# STM32G0B1 register map
File version: 1.5
CPU: CM0 r0p1, little endian, MPU, no FPU, 4 interrupt priority bits
Registers are 32-bit, read-write, reset 0x0 unless marked. A register's access mark holds for its fields unless they carry their own. Offsets are from the block's base; [hi:lo] are bit positions; {n}, {i} and the like mark numbered series.

## RCC — Reset and clock control
Base 0x40021000
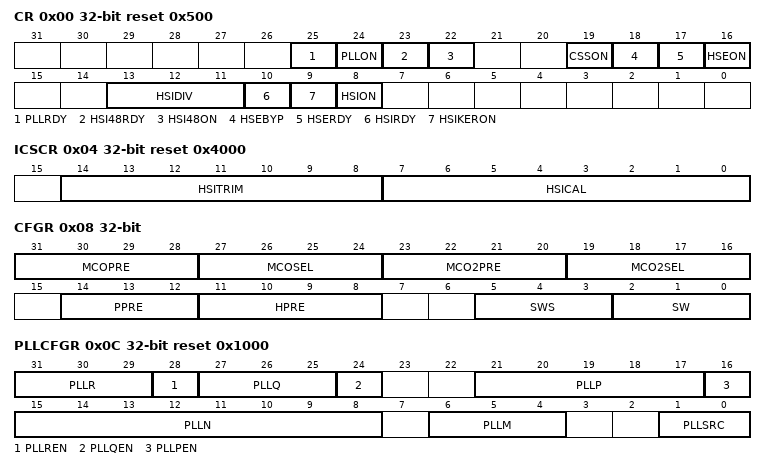
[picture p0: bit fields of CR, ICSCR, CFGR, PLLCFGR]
0x00 CR reset 0x500 — Clock control register
  [25] PLLRDY ro — PLL clock ready flag
  [24] PLLON — PLL enable
  [23] HSI48RDY ro
  [22] HSI48ON
  [19] CSSON — Clock security system enable
  [18] HSEBYP — HSE crystal oscillator bypass
  [17] HSERDY — HSE clock ready flag
  [16] HSEON — HSE clock enable
  [13:11] HSIDIV — HSI16 clock division factor
  [10] HSIRDY ro — HSI16 clock ready flag
  [9] HSIKERON — HSI16 always enable for peripheral kernels
  [8] HSION — HSI16 clock enable
0x04 ICSCR access per field reset 0x4000 — Internal clock sources calibration register
  [14:8] HSITRIM rw — HSI16 clock trimming
  [7:0] HSICAL ro — HSI16 clock calibration
0x08 CFGR access per field — Clock configuration register
  [31:28] MCOPRE rw — Microcontroller clock output prescaler
  [27:24] MCOSEL rw — Microcontroller clock output
  [23:20] MCO2PRE rw
  [19:16] MCO2SEL rw
  [14:12] PPRE rw — APB prescaler
  [11:8] HPRE rw — AHB prescaler
  [5:3] SWS ro — System clock switch status
  [2:0] SW rw — System clock switch
0x0C PLLCFGR reset 0x1000 — PLL configuration register
  [31:29] PLLR — PLL VCO division factor R for PLLRCLK clock output
  [28] PLLREN — PLLRCLK clock output enable
  [27:25] PLLQ — PLL VCO division factor Q for PLLQCLK clock output
  [24] PLLQEN — PLLQCLK clock output enable
  [21:17] PLLP — PLL VCO division factor P for PLLPCLK clock output
  [16] PLLPEN — PLLPCLK clock output enable
  [15:8] PLLN — PLL frequency multiplication factor N
  [6:4] PLLM — Division factor M of the PLL input clock divider
  [1:0] PLLSRC — PLL input clock source
0x14 CRRCR ro — RCC clock recovery RC register
  [8:0] HSI48CAL — HSI48 clock calibration
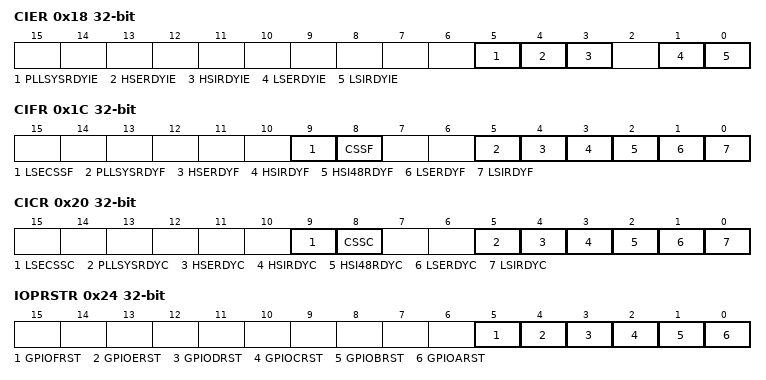
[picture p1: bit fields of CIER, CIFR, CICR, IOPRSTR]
0x18 CIER — Clock interrupt enable register
  [5] PLLSYSRDYIE — PLL ready interrupt enable
  [4] HSERDYIE — HSE ready interrupt enable
  [3] HSIRDYIE — HSI ready interrupt enable
  [1] LSERDYIE — LSE ready interrupt enable
  [0] LSIRDYIE — LSI ready interrupt enable
0x1C CIFR ro — Clock interrupt flag register
  [9] LSECSSF — LSE Clock security system interrupt flag
  [8] CSSF — Clock security system interrupt flag
  [5] PLLSYSRDYF — PLL ready interrupt flag
  [4] HSERDYF — HSE ready interrupt flag
  [3] HSIRDYF — HSI ready interrupt flag
  [2] HSI48RDYF
  [1] LSERDYF — LSE ready interrupt flag
  [0] LSIRDYF — LSI ready interrupt flag
0x20 CICR wo — Clock interrupt clear register
  [9] LSECSSC — LSE Clock security system interrupt clear
  [8] CSSC — Clock security system interrupt clear
  [5] PLLSYSRDYC — PLL ready interrupt clear
  [4] HSERDYC — HSE ready interrupt clear
  [3] HSIRDYC — HSI ready interrupt clear
  [2] HSI48RDYC
  [1] LSERDYC — LSE ready interrupt clear
  [0] LSIRDYC — LSI ready interrupt clear
0x24 IOPRSTR — I/O port reset register
  [5] GPIOFRST, [4] GPIOERST, [3] GPIODRST, [2] GPIOCRST, [1] GPIOBRST, [0] GPIOARST
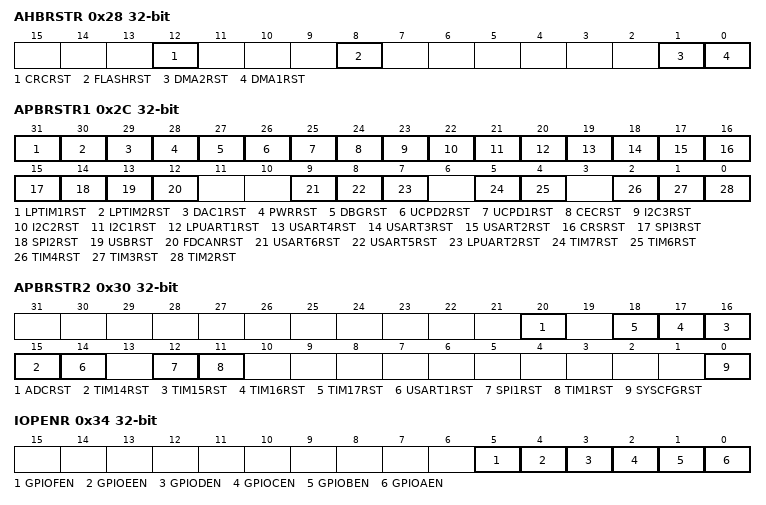
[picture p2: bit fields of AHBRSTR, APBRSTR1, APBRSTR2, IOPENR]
0x28 AHBRSTR — AHB peripheral reset register
  [12] CRCRST — CRC reset
  [8] FLASHRST — FLITF reset
  [1] DMA2RST — DMA1 reset
  [0] DMA1RST — DMA1 reset
0x2C APBRSTR1 — APB peripheral reset register 1
  [31] LPTIM1RST — Low Power Timer 1 reset
  [30] LPTIM2RST — Low Power Timer 2 reset
  [29] DAC1RST — DAC1 interface reset
  [28] PWRRST — Power interface reset
  [27] DBGRST — Debug support reset
  [26] UCPD2RST — UCPD2 reset
  [25] UCPD1RST — UCPD1 reset
  [24] CECRST — HDMI CEC reset
  [23] I2C3RST — I2C3RST reset
  [22] I2C2RST — I2C2 reset
  [21] I2C1RST — I2C1 reset
  [20] LPUART1RST — LPUART1 reset
  [19] USART4RST — USART4 reset
  [18] USART3RST — USART3 reset
  [17] USART2RST — USART2 reset
  [16] CRSRST
  [15] SPI3RST — SPI3 reset
  [14] SPI2RST — SPI2 reset
  [13] USBRST
  [12] FDCANRST
  [9] USART6RST
  [8] USART5RST
  [7] LPUART2RST
  [5] TIM7RST — TIM7 timer reset
  [4] TIM6RST — TIM6 timer reset
  [2] TIM4RST — TIM4 timer reset
  [1] TIM3RST — TIM3 timer reset
  [0] TIM2RST — TIM2 timer reset
0x30 APBRSTR2 — APB peripheral reset register 2
  [20] ADCRST — ADC reset
  [n+1] TIM{n}RST (n=14..17) — TIM{n} timer reset
  [14] USART1RST — USART1 reset
  [12] SPI1RST — SPI1 reset
  [11] TIM1RST — TIM1 timer reset
  [0] SYSCFGRST — SYSCFG, COMP and VREFBUF reset
0x34 IOPENR — GPIO clock enable register
  [5] GPIOFEN — I/O port F clock enable during Sleep mode
  [4] GPIOEEN — I/O port E clock enable during Sleep mode
  [3] GPIODEN — I/O port D clock enable during Sleep mode
  [2] GPIOCEN — I/O port C clock enable during Sleep mode
  [1] GPIOBEN — I/O port B clock enable during Sleep mode
  [0] GPIOAEN — I/O port A clock enable during Sleep mode
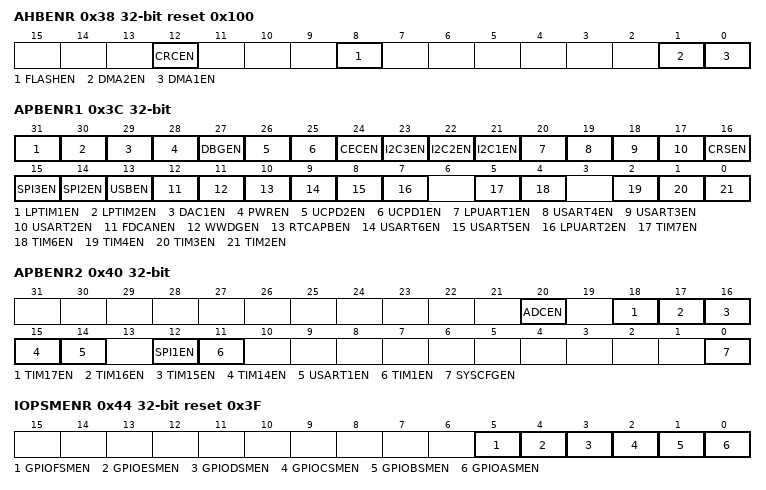
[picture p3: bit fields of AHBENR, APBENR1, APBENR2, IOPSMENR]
0x38 AHBENR reset 0x100 — AHB peripheral clock enable register
  [12] CRCEN — CRC clock enable
  [8] FLASHEN — Flash memory interface clock enable
  [1] DMA2EN — DMA2 clock enable
  [0] DMA1EN — DMA1 clock enable
0x3C APBENR1 — APB peripheral clock enable register 1
  [31] LPTIM1EN — LPTIM1 clock enable
  [30] LPTIM2EN — LPTIM2 clock enable
  [29] DAC1EN — DAC1 interface clock enable
  [28] PWREN — Power interface clock enable
  [27] DBGEN — Debug support clock enable
  [26] UCPD2EN — UCPD2 clock enable
  [25] UCPD1EN — UCPD1 clock enable
  [24] CECEN — HDMI CEC clock enable
  [23] I2C3EN — I2C3 clock enable
  [22] I2C2EN — I2C2 clock enable
  [21] I2C1EN — I2C1 clock enable
  [20] LPUART1EN — LPUART1 clock enable
  [19] USART4EN — USART4 clock enable
  [18] USART3EN — USART3 clock enable
  [17] USART2EN — USART2 clock enable
  [16] CRSEN
  [15] SPI3EN — SPI3 clock enable
  [14] SPI2EN — SPI2 clock enable
  [13] USBEN
  [12] FDCANEN — USBEN
  [11] WWDGEN — WWDG clock enable
  [10] RTCAPBEN — RTC APB clock enable
  [9] USART6EN
  [8] USART5EN
  [7] LPUART2EN — LPUART2 clock enable
  [5] TIM7EN — TIM7 timer clock enable
  [4] TIM6EN — TIM6 timer clock enable
  [2] TIM4EN — TIM4 timer clock enable
  [1] TIM3EN — TIM3 timer clock enable
  [0] TIM2EN — TIM2 timer clock enable
0x40 APBENR2 — APB peripheral clock enable register 2
  [20] ADCEN — ADC clock enable
  [18] TIM17EN — TIM16 timer clock enable
  [17] TIM16EN — TIM16 timer clock enable
  [16] TIM15EN — TIM15 timer clock enable
  [15] TIM14EN — TIM14 timer clock enable
  [14] USART1EN — USART1 clock enable
  [12] SPI1EN — SPI1 clock enable
  [11] TIM1EN — TIM1 timer clock enable
  [0] SYSCFGEN — SYSCFG, COMP and VREFBUF clock enable
0x44 IOPSMENR reset 0x3F — GPIO in Sleep mode clock enable register
  [5] GPIOFSMEN — I/O port F clock enable during Sleep mode
  [4] GPIOESMEN — I/O port E clock enable during Sleep mode
  [3] GPIODSMEN — I/O port D clock enable during Sleep mode
  [2] GPIOCSMEN — I/O port C clock enable during Sleep mode
  [1] GPIOBSMEN — I/O port B clock enable during Sleep mode
  [0] GPIOASMEN — I/O port A clock enable during Sleep mode
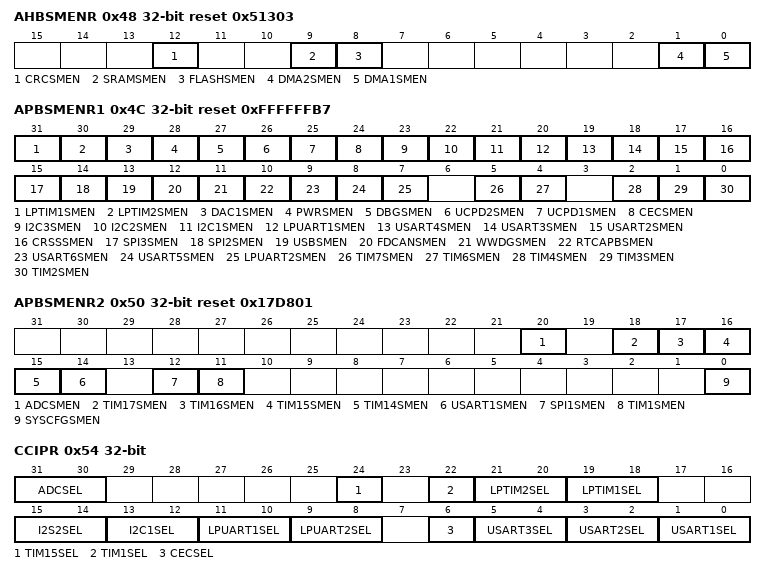
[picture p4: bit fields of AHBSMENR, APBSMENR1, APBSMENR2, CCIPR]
0x48 AHBSMENR reset 0x51303 — AHB peripheral clock enable in Sleep mode register
  [12] CRCSMEN — CRC clock enable during Sleep mode
  [9] SRAMSMEN — SRAM clock enable during Sleep mode
  [8] FLASHSMEN — Flash memory interface clock enable during Sleep mode
  [1] DMA2SMEN — DMA2 clock enable during Sleep mode
  [0] DMA1SMEN — DMA1 clock enable during Sleep mode
0x4C APBSMENR1 reset 0xFFFFFFB7 — APB peripheral clock enable in Sleep mode register 1
  [31] LPTIM1SMEN — Low Power Timer 1 clock enable during Sleep mode
  [30] LPTIM2SMEN — Low Power Timer 2 clock enable during Sleep mode
  [29] DAC1SMEN — DAC1 interface clock enable during Sleep mode
  [28] PWRSMEN — Power interface clock enable during Sleep mode
  [27] DBGSMEN — Debug support clock enable during Sleep mode
  [26] UCPD2SMEN — UCPD2 clock enable during Sleep mode
  [25] UCPD1SMEN — UCPD1 clock enable during Sleep mode
  [24] CECSMEN — HDMI CEC clock enable during Sleep mode
  [23] I2C3SMEN — I2C3 clock enable during Sleep mode
  [22] I2C2SMEN — I2C2 clock enable during Sleep mode
  [21] I2C1SMEN — I2C1 clock enable during Sleep mode
  [20] LPUART1SMEN — LPUART1 clock enable during Sleep mode
  [19] USART4SMEN — USART4 clock enable during Sleep mode
  [18] USART3SMEN — USART3 clock enable during Sleep mode
  [17] USART2SMEN — USART2 clock enable during Sleep mode
  [16] CRSSSMEN — CRSS clock enable during Sleep mode
  [15] SPI3SMEN — SPI3 clock enable during Sleep mode
  [14] SPI2SMEN — SPI2 clock enable during Sleep mode
  [13] USBSMEN — USB clock enable during Sleep mode
  [12] FDCANSMEN — FDCAN clock enable during Sleep mode
  [11] WWDGSMEN — WWDG clock enable during Sleep mode
  [10] RTCAPBSMEN — RTC APB clock enable during Sleep mode
  [9] USART6SMEN — USART6 clock enable
  [8] USART5SMEN — USART5 clock enable
  [7] LPUART2SMEN — LPUART2 clock enable
  [5] TIM7SMEN — TIM7 timer clock enable during Sleep mode
  [4] TIM6SMEN — TIM6 timer clock enable during Sleep mode
  [2] TIM4SMEN — TIM4 timer clock enable during Sleep mode
  [1] TIM3SMEN — TIM3 timer clock enable during Sleep mode
  [0] TIM2SMEN — TIM2 timer clock enable during Sleep mode
0x50 APBSMENR2 reset 0x17D801 — APB peripheral clock enable in Sleep mode register 2
  [20] ADCSMEN — ADC clock enable during Sleep mode
  [18] TIM17SMEN — TIM16 timer clock enable during Sleep mode
  [17] TIM16SMEN — TIM16 timer clock enable during Sleep mode
  [16] TIM15SMEN — TIM15 timer clock enable during Sleep mode
  [15] TIM14SMEN — TIM14 timer clock enable during Sleep mode
  [14] USART1SMEN — USART1 clock enable during Sleep mode
  [12] SPI1SMEN — SPI1 clock enable during Sleep mode
  [11] TIM1SMEN — TIM1 timer clock enable during Sleep mode
  [0] SYSCFGSMEN — SYSCFG, COMP and VREFBUF clock enable during Sleep mode
0x54 CCIPR — Peripherals independent clock configuration register
  [31:30] ADCSEL — ADCs clock source selection
  [24] TIM15SEL — TIM15 clock source selection
  [22] TIM1SEL — TIM1 clock source selection
  [21:20] LPTIM2SEL — LPTIM2 clock source selection
  [19:18] LPTIM1SEL — LPTIM1 clock source selection
  [15:14] I2S2SEL — I2S1 clock source selection
  [13:12] I2C1SEL — I2C1 clock source selection
  [11:10] LPUART1SEL — LPUART1 clock source selection
  [9:8] LPUART2SEL — LPUART2 clock source selection
  [6] CECSEL — HDMI CEC clock source selection
  [5:4] USART3SEL — USART3 clock source selection
  [3:2] USART2SEL — USART2 clock source selection
  [1:0] USART1SEL — USART1 clock source selection
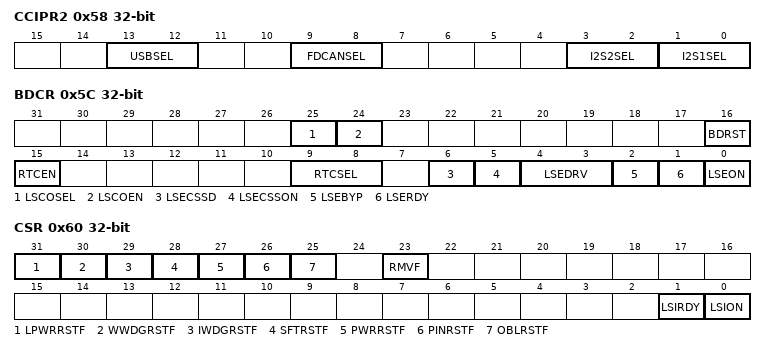
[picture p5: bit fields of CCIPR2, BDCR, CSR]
0x58 CCIPR2 — Peripherals independent clock configuration register 2
  [13:12] USBSEL
  [9:8] FDCANSEL
  [3:2] I2S2SEL
  [1:0] I2S1SEL — 2S1SEL
0x5C BDCR — RTC domain control register
  [25] LSCOSEL — Low-speed clock output selection
  [24] LSCOEN — Low-speed clock output (LSCO) enable
  [16] BDRST — RTC domain software reset
  [15] RTCEN — RTC clock enable
  [9:8] RTCSEL — RTC clock source selection
  [6] LSECSSD ro — CSS on LSE failure Detection
  [5] LSECSSON — CSS on LSE enable
  [4:3] LSEDRV — LSE oscillator drive capability
  [2] LSEBYP — LSE oscillator bypass
  [1] LSERDY ro — LSE oscillator ready
  [0] LSEON — LSE oscillator enable
0x60 CSR — Control/status register
  [31] LPWRRSTF ro — Low-power reset flag
  [30] WWDGRSTF ro — Window watchdog reset flag
  [29] IWDGRSTF ro — Independent window watchdog reset flag
  [28] SFTRSTF ro — Software reset flag
  [27] PWRRSTF ro — BOR or POR/PDR flag
  [26] PINRSTF ro — Pin reset flag
  [25] OBLRSTF ro — Option byte loader reset flag
  [23] RMVF — Remove reset flags
  [1] LSIRDY ro — LSI oscillator ready
  [0] LSION — LSI oscillator enable
